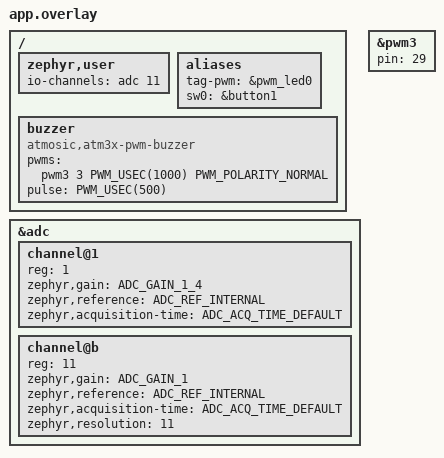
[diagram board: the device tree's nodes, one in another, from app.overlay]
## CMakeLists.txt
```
# Copyright (c) 2025 Atmosic
#
# SPDX-License-Identifier: Apache-2.0

cmake_minimum_required(VERSION 3.20.1)

find_package(Zephyr REQUIRED HINTS $ENV{ZEPHYR_BASE})

add_definitions(-w)
project(ss_fmna_tag)

SET(TAGSDK_PATH "../../../vendor/TagSDK")

include_directories(.)
include_directories(${TAGSDK_PATH}/inc)
include_directories(${TAGSDK_PATH}/conf)
include_directories(${TAGSDK_PATH}/port/inc)
include_directories(${TAGSDK_PATH}/port/atmosic_zephyr)
include_directories(${TAGSDK_PATH}/example/atmosic_zephyr)

add_subdirectory(${TAGSDK_PATH}/example/atmosic_zephyr ./atmosic_zephyr)

target_sources(app PRIVATE
    src/battery.c
    src/main.c
    src/motion.c
    src/sound.c
    )

add_definitions(-DMBEDTLS_ALLOW_PRIVATE_ACCESS -Dmbedtls_sha256_ret=mbedtls_sha256)
zephyr_library_include_directories(${ZEPHYR_BASE}/samples/bluetooth)
zephyr_include_directories(${APPLICATION_SOURCE_DIR}/src/tls_config)
```

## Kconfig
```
# Copyright (c) 2025 Atmosic
#
# SPDX-License-Identifier: Apache-2.0

source "Kconfig.zephyr"

module = SS_FMNA_TAG
module-str = ss_fmna_tag
source "subsys/logging/Kconfig.template.log_config"

config FMNA_DEV_CUSTOM_BT_ADDR
	bool "Enable custom Bluetooth device address for testing or development purposes"

config FMNA_DEV_CUSTOM_BT_ADDR_VALUE
	string "Custom Bluetooth address (MAC format: XX:XX:XX:XX:XX:XX)"
	depends on FMNA_DEV_CUSTOM_BT_ADDR
	default "ED:15:48:87:6E:EF"

config FMNA_PRODUCT_DATA
	string "FMNA Product Data"
	default "DFECEFF1E1FF54DB"

config FMNA_ACCESSORY_CATEGORY
	int "FMNA Accessory Category"
	range 0 255
	default 129

config FMNA_ACCESSORY_CAPABILITY
	int "FMNA Accessory Capability Bit Mask"
	range 0 65535
	default 31
	help
	  Bit 0: Supports play sound
	  Bit 1: Supports motion detector UT
	  Bit 2: Supports serial number lookup by NFC
	  Bit 3: Supports serial number lookup by BLE
	  Bit 4: Supports firmware update service

config FMNA_BATTERY_TYPE
	int "FMNA Battery Type"
	range 0 255
	default 1
	help
	  0: Powered
	  1: Non-rechargeable battery
	  2: Rechargeable battery

config FMNA_PID
	int "FMNA Product ID"
	range 0 65535
	default 51966

config FMNA_MANUFACTURER_NAME
	string "FMNA Manufacturer Name"
	default "Osprey"

config FMNA_MODEL_NAME
	string "FMNA Model Name"
	default "Bike"

config FMNA_HARDWARE_VERSION
	string "FMNA Hardware Version"
	default "1"

config FMNA_VERSION_MAJOR
	int "FMNA Version Major"
	range 0 65535
	default 1

config FMNA_VERSION_MINOR
	int "FMNA Version Minor"
	range 0 65535
	default 0

config FMNA_VERSION_REVISION
	int "FMNA Version Revision"
	range 0 65535
	default 18

config MULTI_MODE
	bool "Multi-Mode (Apple FindMy and Samsung SmartThings) support"
```

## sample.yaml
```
sample:
  description: Samsung Apple ComboTag Application
  name:  Samsung Apple ComboTag
common:
  sysbuild: true
  harness: console
  harness_config:
    type: one_line
    regex:
      - "advP:"
tests:
  applications.ss_fmna_tag.atm:
    tags: ss_fmna_tag atm33 atm34 no_mcuboot
    extra_args:
      - SB_CONFIG_SPE=y
      - SB_ATM_DTS_EXTRA_CPPFLAGS="-DATM_STORAGE_SIZE=0x1000;-DDFU_IN_FLASH"
  applications.ss_fmna_tag.atm.mcuboot:
    tags: ss_fmna_tag atm33 atm34 mcuboot
    extra_args:
      - SB_CONFIG_SPE=y
      - SB_CONFIG_BOOTLOADER_MCUBOOT=y
      - SB_CONFIG_BOOT_SIGNATURE_TYPE_ECDSA_P256=y
      - SB_CONFIG_MCUBOOT_MODE_SWAP_SCRATCH=y
      - SB_ATM_DTS_EXTRA_CPPFLAGS="-DATM_STORAGE_SIZE=0x1000;-DDFU_IN_FLASH"
```

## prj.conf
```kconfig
CONFIG_BT=y
CONFIG_BT_PERIPHERAL=y
CONFIG_BT_GATT_DYNAMIC_DB=y
CONFIG_BT_MAX_CONN=6
CONFIG_BT_RX_STACK_SIZE=4096
CONFIG_BT_L2CAP_TX_MTU=247
CONFIG_BT_BUF_ACL_RX_SIZE=256
CONFIG_BT_SMP=y
CONFIG_BT_SMP_SC_PAIR_ONLY=n
CONFIG_BT_CONN_PARAM_UPDATE_TIMEOUT=6000
CONFIG_BT_ID_MAX=4
CONFIG_BT_EXT_ADV=y
CONFIG_BT_MAX_PAIRED=6
CONFIG_BT_GATT_ENFORCE_SUBSCRIPTION=n
CONFIG_BT_EXT_ADV_MAX_ADV_SET=2
CONFIG_BT_SETTINGS=y
CONFIG_BT_KEYS_OVERWRITE_OLDEST=y

CONFIG_ATM_FMNA=y
CONFIG_ATM_SETTINGS=y
CONFIG_MAX_TX_PWR=4

CONFIG_SETTINGS=y
CONFIG_PM=y

# Kernel
CONFIG_KERNEL_MEM_POOL=y
CONFIG_HEAP_MEM_POOL_SIZE=10240
CONFIG_DEBUG_THREAD_INFO=y
CONFIG_LOG_PROCESS_THREAD_STACK_SIZE=2048
CONFIG_ISR_STACK_SIZE=2048
CONFIG_MAIN_STACK_SIZE=2560
CONFIG_SYSTEM_WORKQUEUE_STACK_SIZE=2048
CONFIG_PRIVILEGED_STACK_SIZE=2048
CONFIG_IDLE_STACK_SIZE=2048

# NVS
CONFIG_FLASH=y
CONFIG_FLASH_MAP=y
CONFIG_FLASH_PAGE_LAYOUT=y
CONFIG_NVS=y
CONFIG_REBOOT=y
CONFIG_MPU_ALLOW_FLASH_WRITE=y

# MBEDTLS
CONFIG_MBEDTLS=y
CONFIG_MBEDTLS_BUILTIN=y
CONFIG_MBEDTLS_ENABLE_HEAP=y
CONFIG_MBEDTLS_HEAP_SIZE=4096
CONFIG_MBEDTLS_ECP_DP_CURVE25519_ENABLED=y
CONFIG_MBEDTLS_KEY_EXCHANGE_PSK_ENABLED=y
CONFIG_MBEDTLS_KEY_EXCHANGE_DHE_PSK_ENABLED=y
CONFIG_MBEDTLS_ECP_NIST_OPTIM=y
CONFIG_MBEDTLS_PEM_CERTIFICATE_FORMAT=y
CONFIG_MBEDTLS_USER_CONFIG_ENABLE=y
CONFIG_MBEDTLS_USER_CONFIG_FILE="user-tls.conf"
CONFIG_MBEDTLS_CIPHER_AES_ENABLED=y
CONFIG_MBEDTLS_ECDH_C=y
CONFIG_MBEDTLS_ECP_C=y
CONFIG_MBEDTLS_MEMORY_DEBUG=n

CONFIG_PWM=y
CONFIG_ADC=y

# Log
CONFIG_LOG=y
CONFIG_LOG_MODE_IMMEDIATE=y

CONFIG_ASSERT=y
CONFIG_EVENTS=y
CONFIG_STREAM_FLASH=y
CONFIG_STREAM_FLASH_ERASE=y
CONFIG_PIPES=y

CONFIG_ATM_BUZZER=y
CONFIG_BATT_MODEL_COIN=y

CONFIG_MULTI_MODE=y
```

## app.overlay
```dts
/*
 * Copyright (c) 2025 Atmosic
 *
 * SPDX-License-Identifier: Apache-2.0
 */

/ {
    zephyr,user {
	io-channels = <&adc 11>;
    };
    aliases {
	tag-pwm = &pwm_led0;
	sw0 = &button1;
    };
    buzzer: buzzer {
	compatible = "atmosic,atm3x-pwm-buzzer";
	pwms = <&pwm3 3 PWM_USEC(1000) PWM_POLARITY_NORMAL>;
	pulse = <PWM_USEC(500)>;
    };
};

&adc {
        #address-cells = <1>;
        #size-cells = <0>;

        channel@1 {
                reg = <1>;
                zephyr,gain = "ADC_GAIN_1_4";
                zephyr,reference = "ADC_REF_INTERNAL";
                zephyr,acquisition-time = <ADC_ACQ_TIME_DEFAULT>;
        };

        channel@b {
                reg = <11>;
                zephyr,gain = "ADC_GAIN_1";
                zephyr,reference = "ADC_REF_INTERNAL";
                zephyr,acquisition-time = <ADC_ACQ_TIME_DEFAULT>;
                zephyr,resolution = <11>;
        };
};

&pwm3 {
	pin = <29>;
	status = "okay";
};
```

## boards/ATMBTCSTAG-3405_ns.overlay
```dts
/* Copyright (c) 2025 Atmosic
 *
 * SPDX-License-Identifier: Apache-2.0
 */

/ {
	zephyr,user {
		io-channels = <&adc 11>;
	};
	aliases {
		tag-pwm = &pwm_led0;
	};
	buzzer: buzzer {
		compatible = "atmosic,atm3x-pwm-buzzer";
		pwms = <&pwm1 1 PWM_USEC(1000) PWM_POLARITY_NORMAL>;
		pulse = <PWM_USEC(500)>;
	};
};

&cpu0 {
	cpu-power-states = <&idle &sleep &retain &hibernate &soc_off>;
};

&adc {
	#address-cells = <1>;
	#size-cells = <0>;

	channel@1 {
		reg = <1>;
		zephyr,gain = "ADC_GAIN_1_8";
		zephyr,reference = "ADC_REF_INTERNAL";
		zephyr,acquisition-time = <ADC_ACQ_TIME_DEFAULT>;
	};

	channel@b {
		reg = <11>;
		zephyr,gain = "ADC_GAIN_1_2";
		zephyr,reference = "ADC_REF_INTERNAL";
		zephyr,acquisition-time = <ADC_ACQ_TIME_DEFAULT>;
		zephyr,resolution = <15>;
	};
};
```

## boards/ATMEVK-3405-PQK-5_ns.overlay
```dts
/*
 * Copyright (c) 2025 Atmosic
 *
 * SPDX-License-Identifier: Apache-2.0
 */

/ {
    zephyr,user {
	io-channels = <&adc 11>;
    };
    aliases {
	tag-pwm = &pwm_led0;
	sw0 = &button1;
    };
     buzzer: buzzer {
	compatible = "atmosic,atm3x-pwm-buzzer";
	pwms = <&pwm7 7 PWM_USEC(1000) PWM_POLARITY_NORMAL>;
	pulse = <PWM_USEC(500)>;
    };
};

&pwm7 {
	pin = <7>;
	status = "okay";
};

&adc {
        #address-cells = <1>;
        #size-cells = <0>;

        channel@1 {
                reg = <1>;
                zephyr,gain = "ADC_GAIN_1_8";
                zephyr,reference = "ADC_REF_INTERNAL";
                zephyr,acquisition-time = <ADC_ACQ_TIME_DEFAULT>;
        };

        channel@b {
                reg = <11>;
                zephyr,gain = "ADC_GAIN_1_2";
                zephyr,reference = "ADC_REF_INTERNAL";
                zephyr,acquisition-time = <ADC_ACQ_TIME_DEFAULT>;
                zephyr,resolution = <15>;
        };
};
```

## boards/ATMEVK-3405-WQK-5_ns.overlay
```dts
/*
 * Copyright (c) 2025 Atmosic
 *
 * SPDX-License-Identifier: Apache-2.0
 */

/ {
    zephyr,user {
	io-channels = <&adc 11>;
    };
    aliases {
	tag-pwm = &pwm_led0;
	sw0 = &button1;
    };
    buzzer: buzzer {
	compatible = "atmosic,atm3x-pwm-buzzer";
	pwms = <&pwm7 7 PWM_USEC(1000) PWM_POLARITY_NORMAL>;
	pulse = <PWM_USEC(500)>;
    };
};

&pwm7 {
	pin = <7>;
	status = "okay";
};

&adc {
        #address-cells = <1>;
        #size-cells = <0>;

        channel@1 {
                reg = <1>;
                zephyr,gain = "ADC_GAIN_1_8";
                zephyr,reference = "ADC_REF_INTERNAL";
                zephyr,acquisition-time = <ADC_ACQ_TIME_DEFAULT>;
        };

        channel@b {
                reg = <11>;
                zephyr,gain = "ADC_GAIN_1_2";
                zephyr,reference = "ADC_REF_INTERNAL";
                zephyr,acquisition-time = <ADC_ACQ_TIME_DEFAULT>;
                zephyr,resolution = <15>;
        };
};
```

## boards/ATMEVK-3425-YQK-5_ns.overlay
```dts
/*
 * Copyright (c) 2025 Atmosic
 *
 * SPDX-License-Identifier: Apache-2.0
 */

/ {
    zephyr,user {
	io-channels = <&adc 11>;
    };
    aliases {
	tag-pwm = &pwm_led0;
	sw0 = &button1;
    };
	buzzer: buzzer {
	compatible = "atmosic,atm3x-pwm-buzzer";
	pwms = <&pwm3 3 PWM_USEC(1000) PWM_POLARITY_NORMAL>;
	pulse = <PWM_USEC(500)>;
    };
};

&pwm3 {
	pin = <29>;
	status = "okay";
};

&adc {
        #address-cells = <1>;
        #size-cells = <0>;

        channel@1 {
                reg = <1>;
                zephyr,gain = "ADC_GAIN_1_8";
                zephyr,reference = "ADC_REF_INTERNAL";
                zephyr,acquisition-time = <ADC_ACQ_TIME_DEFAULT>;
        };

        channel@b {
                reg = <11>;
                zephyr,gain = "ADC_GAIN_1_2";
                zephyr,reference = "ADC_REF_INTERNAL";
                zephyr,acquisition-time = <ADC_ACQ_TIME_DEFAULT>;
                zephyr,resolution = <15>;
        };
};
```

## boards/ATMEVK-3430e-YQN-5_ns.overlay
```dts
/*
 * Copyright (c) 2025 Atmosic
 *
 * SPDX-License-Identifier: Apache-2.0
 */

/ {
    zephyr,user {
	io-channels = <&adc 11>;
    };
    aliases {
	tag-pwm = &pwm_led0;
	sw0 = &button1;
    };
    buzzer: buzzer {
	compatible = "atmosic,atm3x-pwm-buzzer";
	pwms = <&pwm3 3 PWM_USEC(1000) PWM_POLARITY_NORMAL>;
	pulse = <PWM_USEC(500)>;
    };
};

&pwm3 {
	pin = <29>;
	status = "okay";
};

&adc {
        #address-cells = <1>;
        #size-cells = <0>;

        channel@1 {
                reg = <1>;
                zephyr,gain = "ADC_GAIN_1_8";
                zephyr,reference = "ADC_REF_INTERNAL";
                zephyr,acquisition-time = <ADC_ACQ_TIME_DEFAULT>;
        };

        channel@b {
                reg = <11>;
                zephyr,gain = "ADC_GAIN_1_2";
                zephyr,reference = "ADC_REF_INTERNAL";
                zephyr,acquisition-time = <ADC_ACQ_TIME_DEFAULT>;
                zephyr,resolution = <15>;
        };
};
```

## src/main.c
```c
/*
 * Copyright (c) 2025 Atmosic
 *
 * SPDX-License-Identifier: Apache-2.0
 */

#include <zephyr/kernel.h>
#include <zephyr/sys/printk.h>
#include <zephyr/types.h>
#include <zephyr/logging/log.h>
#include <zephyr/settings/settings.h>
#include <zephyr/bluetooth/bluetooth.h>
#include <zephyr/drivers/gpio.h>

#include "TagSdk.h"
#include "arch.h"
#include "app_work_q.h"
#include "fmna_api.h"
#include "reset.h"
#include "sound.h"
#include "motion.h"
#include "battery.h"

LOG_MODULE_REGISTER(ss_fmna_tag, CONFIG_SS_FMNA_TAG_LOG_LEVEL);

static char const * const fmna_state_string[] = {
    "FMNA_STATE_INIT_DONE",
    "FMNA_STATE_UNPAIRED",
    "FMNA_STATE_PAIRING",
    "FMNA_STATE_PAIRED",
};

static void state_notify(fmna_state_notify_t state)
{
    LOG_INF("FMNA current state %s", fmna_state_string[state]);
    switch (state) {
	case FMNA_STATE_INIT_DONE:
	    if (!fmna_connection_is_fmna_paired()) {
		fmna_main_start_pairing_adv();
	    }
	    break;
	default:
	    break;
    }
}

#define BUTTON0 DT_ALIAS(sw0)
#if DT_NODE_EXISTS(BUTTON0)

static void fmna_reset_pairing_work_handler(struct k_work *work)
{
    fmna_main_reset_pairing_state();
}

K_WORK_DEFINE(fmna_reset_pairing_work, fmna_reset_pairing_work_handler);

static const struct gpio_dt_spec button = GPIO_DT_SPEC_GET(BUTTON0, gpios);
static void gpio_init_detect_unpair(void)
{
    LOG_INF("gpio_init_detect_unpair");

    if (!is_boot_type(TYPE_POWER_ON)) {
	return;
    }

    int err = gpio_pin_configure_dt(&button, GPIO_INPUT);
    if (err) {
	LOG_ERR("Error %d: failed to configure %s pin %u", err,
	    button.port->name, button.pin);
	return;
    }

    if (!gpio_pin_get_dt(&button)) {
	return;
    }

    LOG_INF("Button pressed, perform FMNA unpair");
    // defer reset_pairing to app_work_q so the main stack size can be reduced.
    atm_work_submit_to_app_work_q(&fmna_reset_pairing_work);
}
#else
#warning "Check if User Button is correct for your target board."
#endif

#ifdef CONFIG_FMNA_DEV_CUSTOM_BT_ADDR
static bt_addr_le_t init_addr;
#endif

static uint8_t product_data[8];
static struct fmna_init_params const fmna_init_params = {
#ifdef CONFIG_FMNA_DEV_CUSTOM_BT_ADDR
    .init_addr = init_addr.a.val,
#endif
    .acc_capability = CONFIG_FMNA_ACCESSORY_CAPABILITY,
    .acc_category = CONFIG_FMNA_ACCESSORY_CATEGORY,
    .batt_type = CONFIG_FMNA_BATTERY_TYPE,
    .pid = CONFIG_FMNA_PID,
    .product_data = product_data,
    .manufacturer_name = CONFIG_FMNA_MANUFACTURER_NAME,
    .model_name = CONFIG_FMNA_MODEL_NAME,
    .hardware_version = CONFIG_FMNA_HARDWARE_VERSION,
    .version_major = CONFIG_FMNA_VERSION_MAJOR,
    .version_minor = CONFIG_FMNA_VERSION_MINOR,
    .version_revision = CONFIG_FMNA_VERSION_REVISION,
    .sound_cb = {
	.sound_init = sound_init,
	.sound_start = sound_start,
	.sound_stop = sound_stop
    },
    .motion_cb = {
	.motion_init = motion_init,
	.motion_deinit = motion_deinit,
	.motion_detected = motion_detected
    },
    .battery_cb = {
	.battery_level_get = battery_level_get
    },
    .state_cb = {
	.state_notify = state_notify,
    }
};

static void fmna_init_work_handler(struct k_work *work)
{
#ifdef CONFIG_FMNA_DEV_CUSTOM_BT_ADDR
    int err = bt_addr_le_from_str(CONFIG_FMNA_DEV_CUSTOM_BT_ADDR_VALUE,
	"random", &init_addr);
    if (err) {
	LOG_ERR("Invalid Bluetooth address format");
	return;
    }
#endif
    hex2bin(CONFIG_FMNA_PRODUCT_DATA, strlen(CONFIG_FMNA_PRODUCT_DATA),
	product_data, sizeof(product_data));

    fmna_main_init(&fmna_init_params);
}

K_WORK_DEFINE(fmna_init_work, fmna_init_work_handler);

int main(void)
{
#if DT_NODE_EXISTS(BUTTON0)
    gpio_init_detect_unpair();
#endif
    printk("Tag DEMO! %s-%s-%s\n", CONFIG_BOARD, __DATE__, __TIME__);

    TagResult_t result;

    result = TagInit();
    if (result != TAG_RESULT_SUCCESS) {
	printk("Failed to init:%d\n", result);
	return -1;
    }

    int err = bt_enable(0);
    if (err) {
	printk("Failed to init bt :%d\n", err);
	return -1;
    }

    result = TagStart();
    if (result != TAG_RESULT_SUCCESS) {
	printk("Failed to start MainTask:%d\n", result);
	return -1;
    }

    LOG_INF("Bluetooth initialized");

    err = settings_load();
    if (err) {
	LOG_ERR("settings_load failed (err %d)", err);
	return;
    }

    LOG_INF("Check pairing status: %u", fmna_connection_is_fmna_paired());
    // defer fmna_init to app_work_q so the main stack size can be reduced.
    atm_work_submit_to_app_work_q(&fmna_init_work);
    return 0;
}
```

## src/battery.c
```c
/*
 * Copyright (c) 2025 Atmosic
 *
 * SPDX-License-Identifier: Apache-2.0
 */

#include <zephyr/types.h>
#include <zephyr/logging/log.h>
#include <stdbool.h>
#include "fmna_api.h"
#include "battery.h"

LOG_MODULE_REGISTER(battery, CONFIG_SS_FMNA_TAG_LOG_LEVEL);

static fmna_bat_state_level_t last_lvl = BAT_STATE_FULL;

#ifdef CONFIG_BATT_MODEL
#include <zephyr/device.h>
#include <zephyr/init.h>
#include "batt_model.h"

static void batt_sample_cb(uint16_t lvl, int32_t mvolt)
{
    ARG_UNUSED(mvolt);
    if (lvl > 8500) {
	last_lvl = BAT_STATE_FULL;
    } else if (lvl > 3000) {
	last_lvl = BAT_STATE_MEDIUM;
    } else if (lvl > 1000) {
	last_lvl = BAT_STATE_LOW;
    } else {
	last_lvl = BAT_STATE_CRITICALLY_LOW;
    }
}

static int batt_model_init(void)
{
    batt_model()->init(NULL);
    return 0;
}

SYS_INIT(batt_model_init, POST_KERNEL, CONFIG_APPLICATION_INIT_PRIORITY);
#endif

fmna_bat_state_level_t battery_level_get(void)
{
#ifdef CONFIG_BATT_MODEL
    batt_model()->sample(batt_sample_cb);
#endif
    LOG_DBG("Battery level: %d\n", last_lvl);
    return last_lvl;
}
```

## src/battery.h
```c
/*
 * Copyright (c) 2025 Atmosic
 *
 * SPDX-License-Identifier: Apache-2.0
 */

#pragma once

#ifdef __cplusplus
extern "C" {
#endif

/**
 * @brief Battery get level
 * @return Battery level
 */
fmna_bat_state_level_t battery_level_get(void);

#ifdef __cplusplus
}
#endif
```

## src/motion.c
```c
/*
 * Copyright (c) 2025 Atmosic
 *
 * SPDX-License-Identifier: Apache-2.0
 */

#include <zephyr/types.h>
#include <zephyr/logging/log.h>
#include <stdbool.h>
#include "motion.h"

LOG_MODULE_REGISTER(motion, CONFIG_SS_FMNA_TAG_LOG_LEVEL);

void motion_init(void)
{
    // Initialize motion detection
    LOG_DBG("motion_init");
}

void motion_deinit(void)
{
    // Deinitialize motion detection
    LOG_DBG("motion_deinit");
}

bool motion_detected(void)
{
    // Check if motion is detected
    LOG_DBG("motion_detected");
    return false;
}
```

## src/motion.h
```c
/*
 * Copyright (c) 2025 Atmosic
 *
 * SPDX-License-Identifier: Apache-2.0
 */

#pragma once

#ifdef __cplusplus
extern "C" {
#endif

/**
 * @brief Initialize motion detection
 */
void motion_init(void);

/**
 * @brief Deinitialize motion detection
 */
void motion_deinit(void);

/**
 * @brief Check if motion is detected
 * @return true if motion is detected
 */
bool motion_detected(void);

#ifdef __cplusplus
}
#endif
```

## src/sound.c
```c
/*
 * Copyright (c) 2025 Atmosic
 *
 * SPDX-License-Identifier: Apache-2.0
 */

#include <zephyr/types.h>
#include <zephyr/logging/log.h>
#include "sound.h"

#ifdef CONFIG_ATM_BUZZER
#include <zephyr/drivers/pwm.h>
#include <zephyr/device.h>
#include <zephyr/kernel.h>
#include "atm_buzzer.h"

#define BUZZER_NODE DT_NODELABEL(buzzer)
#define BUZZER_PWM_NODE DT_PHANDLE(BUZZER_NODE, pwms)
BUILD_ASSERT(DT_NODE_EXISTS(BUZZER_NODE),
    "BUZZER_NODE does not exist in the Device Tree!");

static atm_buzzer_t buzzer_cfg = {
    .pwm_dt = PWM_DT_SPEC_GET(BUZZER_NODE),
    .pulse = DT_PROP(BUZZER_NODE, pulse),
    .min_frequency = DT_PROP(BUZZER_PWM_NODE, min_frequency),
    .max_frequency = DT_PROP(BUZZER_PWM_NODE, max_frequency),
};
#endif
LOG_MODULE_REGISTER(sound, CONFIG_SS_FMNA_TAG_LOG_LEVEL);

void sound_init(void)
{
    // Initialize sound
    LOG_DBG("sound_init");
}

void sound_start(void)
{
#ifdef CONFIG_ATM_BUZZER
    atm_buzzer_onoff(&buzzer_cfg, true);
#endif
    LOG_DBG("sound_start");
}

void sound_stop(void)
{
#ifdef CONFIG_ATM_BUZZER
    atm_buzzer_onoff(&buzzer_cfg, false);
#endif
    LOG_DBG("sound_stop");
}
```
